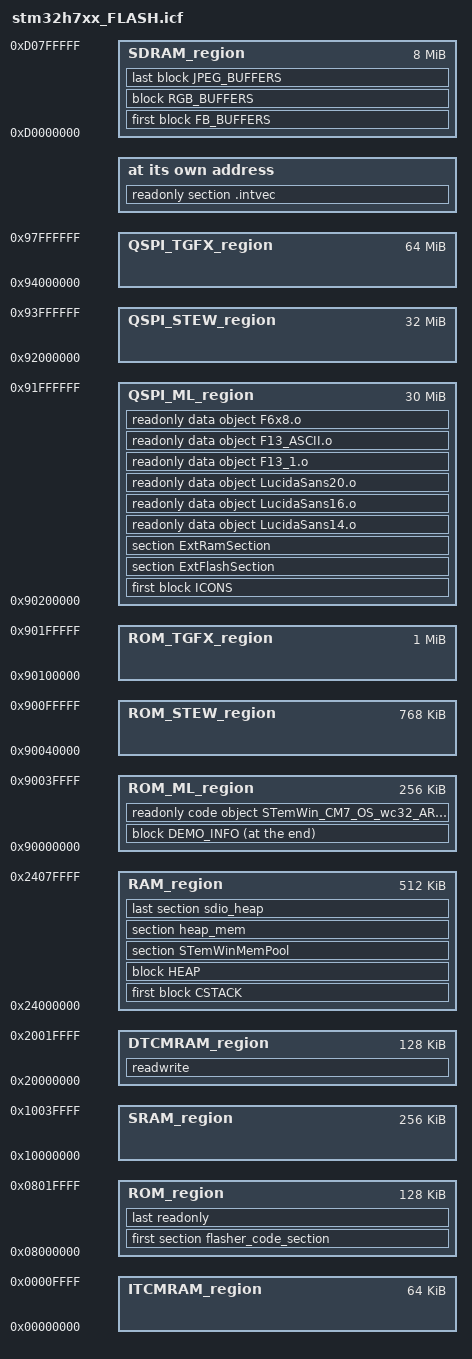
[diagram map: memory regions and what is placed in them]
/*###ICF### Section handled by ICF editor, don't touch! ****/
/*-Editor annotation file-*/
/* IcfEditorFile="$TOOLKIT_DIR$\config\ide\IcfEditor\cortex_v1_0.xml" */
/*-Specials-*/
define symbol __ICFEDIT_intvec_start__ = __C_START_ADDR; /* 0x08000000 */
/*-Memory Regions-*/
define symbol __ICFEDIT_region_ROM_start__        = 0x08000000;
define symbol __ICFEDIT_region_ROM_end__          = 0x0801FFFF; /*  128 Kbytes for the Menu Launcher */

define symbol __ICFEDIT_region_ROM_ML_start__     = 0x90000000;
define symbol __ICFEDIT_region_ROM_ML_end__       = 0x9003FFFF; /*  256 Kbytes for the Menu Launcher */
define symbol __ICFEDIT_region_ROM_STEW_start__   = 0x90040000;
define symbol __ICFEDIT_region_ROM_STEW_end__     = 0x900FFFFF; /*  768 Kbytes for STemWin demo */
define symbol __ICFEDIT_region_ROM_TGFX_start__   = 0x90100000;
define symbol __ICFEDIT_region_ROM_TGFX_end__     = 0x901FFFFF; /* 1024 Kbytes for TouchGFX demo */

/*-Internal RAM Memory Regions-*/
define symbol __ICFEDIT_region_ITCMRAM_start__    = 0x00000000;
define symbol __ICFEDIT_region_ITCMRAM_end__      = 0x0000FFFF; /*  64 Kbytes */
define symbol __ICFEDIT_region_DTCMRAM_start__    = 0x20000000;
define symbol __ICFEDIT_region_DTCMRAM_end__      = 0x2001FFFF; /* 128 Kbytes */
define symbol __ICFEDIT_region_SRAM_start__       = 0x10000000;
define symbol __ICFEDIT_region_SRAM_end__         = 0x1003FFFF; /* 256 Kbytes */
define symbol __ICFEDIT_region_RAM_start__        = 0x24000000;
define symbol __ICFEDIT_region_RAM_end__          = 0x2407FFFF; /* 512 Kbytes */

/*-External RAM Memory Regions-*/
define symbol __ICFEDIT_region_SDRAM_start__      = 0xD0000000; /*   8 Mbytes */
define symbol __ICFEDIT_region_SDRAM_end__        = 0xD07FFFFF;

/*-Quad-SPI Memory Regions-*/
define symbol __ICFEDIT_region_QSPI_ML_start__    = 0x90200000;
define symbol __ICFEDIT_region_QSPI_ML_end__      = 0x91FFFFFF; /* 30 Mbytes for the MenuLauncher */
define symbol __ICFEDIT_region_QSPI_STEW_start__  = 0x92000000;
define symbol __ICFEDIT_region_QSPI_STEW_end__    = 0x93FFFFFF; /* 32 Mbytes for STemWin demo */
define symbol __ICFEDIT_region_QSPI_TGFX_start__  = 0x94000000;
define symbol __ICFEDIT_region_QSPI_TGFX_end__    = 0x97FFFFFF; /* 64 Mbytes for TouchGFX demo */

/*-Sizes-*/
define symbol __ICFEDIT_size_cstack__ = 0x800;  /* 2 Kb */
define symbol __ICFEDIT_size_heap__   = 0x800;  /* 2 Kb */
/**** End of ICF editor section. ###ICF###*/

define memory mem with size = 4G;
define region ROM_region        = mem:[from __ICFEDIT_region_ROM_start__        to __ICFEDIT_region_ROM_end__];
define region ROM_ML_region     = mem:[from __ICFEDIT_region_ROM_ML_start__     to __ICFEDIT_region_ROM_ML_end__];
define region ROM_STEW_region   = mem:[from __ICFEDIT_region_ROM_STEW_start__   to __ICFEDIT_region_ROM_STEW_end__];
define region ROM_TGFX_region   = mem:[from __ICFEDIT_region_ROM_TGFX_start__   to __ICFEDIT_region_ROM_TGFX_end__];

define region ITCMRAM_region    = mem:[from __ICFEDIT_region_ITCMRAM_start__    to __ICFEDIT_region_ITCMRAM_end__];
define region DTCMRAM_region    = mem:[from __ICFEDIT_region_DTCMRAM_start__    to __ICFEDIT_region_DTCMRAM_end__];
define region SRAM_region       = mem:[from __ICFEDIT_region_SRAM_start__       to __ICFEDIT_region_SRAM_end__];
define region RAM_region        = mem:[from __ICFEDIT_region_RAM_start__        to __ICFEDIT_region_RAM_end__];
define region SDRAM_region      = mem:[from __ICFEDIT_region_SDRAM_start__      to __ICFEDIT_region_SDRAM_end__];

define region QSPI_ML_region    = mem:[from __ICFEDIT_region_QSPI_ML_start__    to __ICFEDIT_region_QSPI_ML_end__];
define region QSPI_STEW_region  = mem:[from __ICFEDIT_region_QSPI_STEW_start__  to __ICFEDIT_region_QSPI_STEW_end__];
define region QSPI_TGFX_region  = mem:[from __ICFEDIT_region_QSPI_TGFX_start__  to __ICFEDIT_region_QSPI_TGFX_end__];

define block CSTACK     with alignment = 8, size = __ICFEDIT_size_cstack__    { };
define block HEAP       with alignment = 8, size = __ICFEDIT_size_heap__      { };
define block DEMO_INFO  with alignment = 8, size = 0x800                      { section DemoContextSection };
define block ICONS      with alignment = 32, fixed order                      { section default_icon_section
                                                                              , section default_logo_section
                                                                              , section splash_st_section };
define block FB_BUFFERS with alignment = 32, fixed order                      { section framebuffer };
define block JPEG_BUFFERS with alignment = 32                                 { section jpeg_decoder_buffers };
define block RGB_BUFFERS with alignment = 32                                  { section rgb_video_buffers };

initialize by copy { readwrite };
// initialize manually { readonly data section ExtRamSection };
do not initialize  { section .noinit, section framebuffer };
do not initialize  { section jpeg_decoder_buffers, section rgb_video_buffers };

place at address mem:__ICFEDIT_intvec_start__ { readonly section .intvec };
place at end of ROM_ML_region { block DEMO_INFO };

place in ITCMRAM_region     { };
place in DTCMRAM_region     { readwrite };
place in RAM_region         { first block CSTACK, block HEAP, section STemWinMemPool
                            , section heap_mem, last section sdio_heap };
place in SDRAM_region       { first block FB_BUFFERS, block RGB_BUFFERS
                            , last block JPEG_BUFFERS };

place in ROM_region         { first section flasher_code_section
                            , last readonly };

place in ROM_ML_region      { readonly code object STemWin_CM7_OS_wc32_ARGB.a };

place in QSPI_ML_region     { first block ICONS
                            , section ExtFlashSection
                            , section ExtRamSection
                            , readonly data object LucidaSans14.o
                            , readonly data object LucidaSans16.o
                            , readonly data object LucidaSans20.o
                            , readonly data object F13_1.o
                            , readonly data object F13_ASCII.o
                            , readonly data object F6x8.o };
